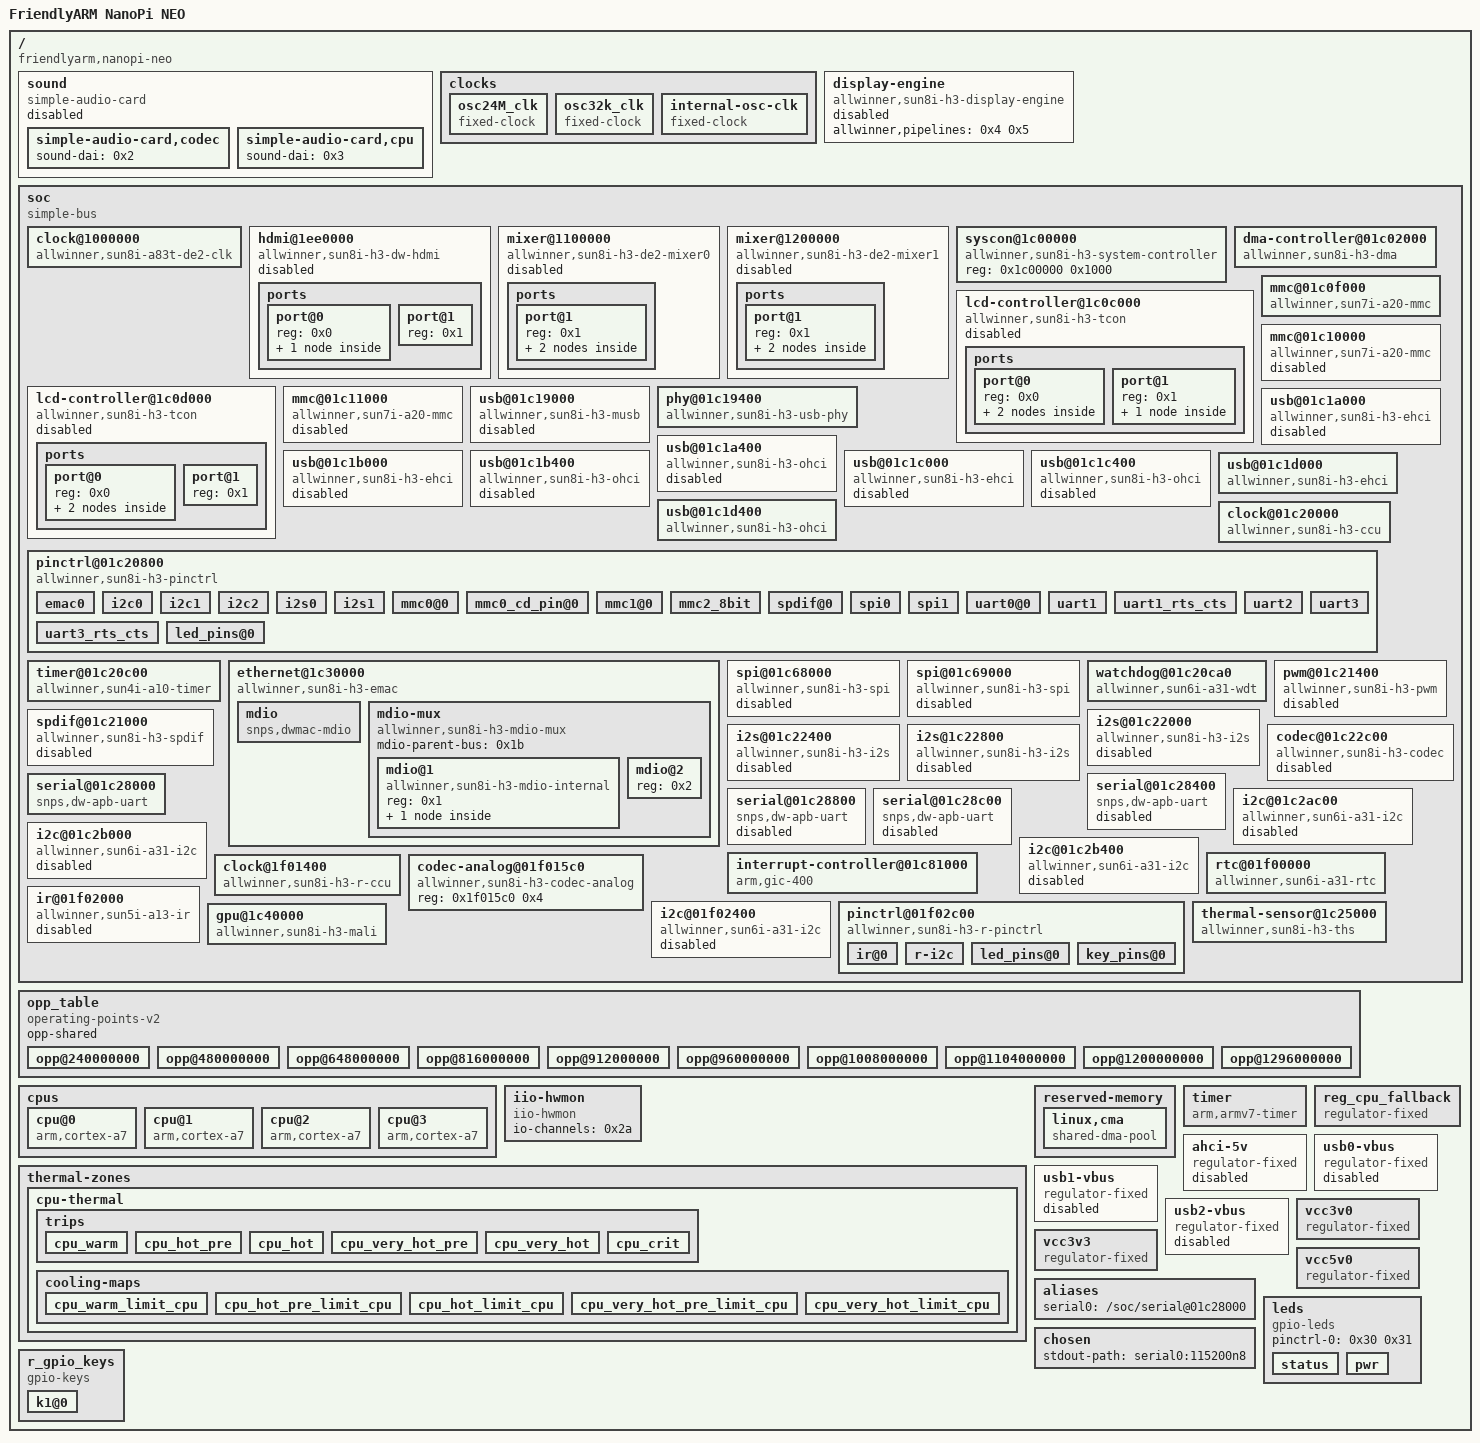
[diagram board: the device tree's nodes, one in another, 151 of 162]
/dts-v1/;

/ {
	interrupt-parent = <0x1>;
	#address-cells = <0x1>;
	#size-cells = <0x1>;
	model = "FriendlyARM NanoPi NEO";
	compatible = "friendlyarm,nanopi-neo", "allwinner,sun8i-h3";

	sound {
		compatible = "simple-audio-card";
		simple-audio-card,format = "i2s";
		simple-audio-card,name = "allwinner,hdmi";
		simple-audio-card,mclk-fs = <0x100>;
		status = "disabled";
		linux,phandle = <0x34>;
		phandle = <0x34>;

		simple-audio-card,codec {
			sound-dai = <0x2>;
		};

		simple-audio-card,cpu {
			sound-dai = <0x3>;
		};
	};

	clocks {
		#address-cells = <0x1>;
		#size-cells = <0x1>;
		ranges;

		osc24M_clk {
			#clock-cells = <0x0>;
			compatible = "fixed-clock";
			clock-frequency = <0x16e3600>;
			clock-output-names = "osc24M";
			linux,phandle = <0x17>;
			phandle = <0x17>;
		};

		osc32k_clk {
			#clock-cells = <0x0>;
			compatible = "fixed-clock";
			clock-frequency = <0x8000>;
			clock-output-names = "osc32k";
			linux,phandle = <0x18>;
			phandle = <0x18>;
		};

		internal-osc-clk {
			#clock-cells = <0x0>;
			compatible = "fixed-clock";
			clock-frequency = <0xf42400>;
			clock-accuracy = <0x11e1a300>;
			clock-output-names = "iosc";
			linux,phandle = <0x24>;
			phandle = <0x24>;
		};
	};

	display-engine {
		compatible = "allwinner,sun8i-h3-display-engine";
		allwinner,pipelines = <0x4 0x5>;
		status = "disabled";
		linux,phandle = <0x35>;
		phandle = <0x35>;
	};

	soc {
		compatible = "simple-bus";
		#address-cells = <0x1>;
		#size-cells = <0x1>;
		ranges;

		clock@1000000 {
			reg = <0x1000000 0x100000>;
			clocks = <0x6 0x30 0x6 0x65>;
			clock-names = "bus", "mod";
			resets = <0x6 0x22>;
			#clock-cells = <0x1>;
			#reset-cells = <0x1>;
			assigned-clocks = <0x6 0x65>;
			assigned-clock-parents = <0x6 0xd>;
			assigned-clock-rates = <0x19bfcc00>;
			compatible = "allwinner,sun8i-a83t-de2-clk";
			linux,phandle = <0x8>;
			phandle = <0x8>;
		};

		hdmi@1ee0000 {
			#sound-dai-cells = <0x0>;
			compatible = "allwinner,sun8i-h3-dw-hdmi";
			reg = <0x1ee0000 0x10000 0x1ef0000 0x10000>;
			reg-io-width = <0x1>;
			interrupts = <0x0 0x58 0x4>;
			clocks = <0x6 0x2f 0x6 0x6f 0x6 0x70>;
			clock-names = "iahb", "isfr", "ddc";
			resets = <0x6 0x20 0x6 0x21>;
			reset-names = "hdmi", "ddc";
			status = "disabled";
			linux,phandle = <0x2>;
			phandle = <0x2>;

			ports {
				#address-cells = <0x1>;
				#size-cells = <0x0>;

				port@0 {
					#address-cells = <0x1>;
					#size-cells = <0x0>;
					reg = <0x0>;
					linux,phandle = <0x36>;
					phandle = <0x36>;

					endpoint@0 {
						reg = <0x0>;
						remote-endpoint = <0x7>;
						linux,phandle = <0xf>;
						phandle = <0xf>;
					};
				};

				port@1 {
					#address-cells = <0x1>;
					#size-cells = <0x0>;
					reg = <0x1>;
					linux,phandle = <0x37>;
					phandle = <0x37>;
				};
			};
		};

		mixer@1100000 {
			compatible = "allwinner,sun8i-h3-de2-mixer0";
			reg = <0x1100000 0x100000>;
			clocks = <0x8 0x0 0x8 0x6>;
			clock-names = "bus", "mod";
			resets = <0x8 0x0>;
			status = "disabled";
			linux,phandle = <0x4>;
			phandle = <0x4>;

			ports {
				#address-cells = <0x1>;
				#size-cells = <0x0>;

				port@1 {
					#address-cells = <0x1>;
					#size-cells = <0x0>;
					reg = <0x1>;
					linux,phandle = <0x38>;
					phandle = <0x38>;

					endpoint@0 {
						reg = <0x0>;
						remote-endpoint = <0x9>;
						linux,phandle = <0xd>;
						phandle = <0xd>;
					};

					endpoint@1 {
						reg = <0x1>;
						remote-endpoint = <0xa>;
						linux,phandle = <0x10>;
						phandle = <0x10>;
					};
				};
			};
		};

		mixer@1200000 {
			compatible = "allwinner,sun8i-h3-de2-mixer1";
			reg = <0x1200000 0x100000>;
			clocks = <0x8 0x1 0x8 0x7>;
			clock-names = "bus", "mod";
			status = "disabled";
			resets = <0x8 0x2>;
			linux,phandle = <0x5>;
			phandle = <0x5>;

			ports {
				#address-cells = <0x1>;
				#size-cells = <0x0>;

				port@1 {
					#address-cells = <0x1>;
					#size-cells = <0x0>;
					reg = <0x1>;
					linux,phandle = <0x39>;
					phandle = <0x39>;

					endpoint@0 {
						reg = <0x0>;
						remote-endpoint = <0xb>;
						linux,phandle = <0xe>;
						phandle = <0xe>;
					};

					endpoint@1 {
						reg = <0x1>;
						remote-endpoint = <0xc>;
						linux,phandle = <0x11>;
						phandle = <0x11>;
					};
				};
			};
		};

		syscon@1c00000 {
			compatible = "allwinner,sun8i-h3-system-controller", "syscon";
			reg = <0x1c00000 0x1000>;
			linux,phandle = <0x19>;
			phandle = <0x19>;
		};

		dma-controller@01c02000 {
			compatible = "allwinner,sun8i-h3-dma";
			reg = <0x1c02000 0x1000>;
			interrupts = <0x0 0x32 0x4>;
			clocks = <0x6 0x15>;
			resets = <0x6 0x6>;
			#dma-cells = <0x1>;
			linux,phandle = <0x1c>;
			phandle = <0x1c>;
		};

		lcd-controller@1c0c000 {
			compatible = "allwinner,sun8i-h3-tcon";
			reg = <0x1c0c000 0x1000>;
			interrupts = <0x0 0x56 0x4>;
			clocks = <0x6 0x2a 0x6 0x66>;
			clock-names = "ahb", "tcon-ch1";
			resets = <0x6 0x1b>;
			reset-names = "lcd";
			status = "disabled";
			linux,phandle = <0x3a>;
			phandle = <0x3a>;

			ports {
				#address-cells = <0x1>;
				#size-cells = <0x0>;

				port@0 {
					#address-cells = <0x1>;
					#size-cells = <0x0>;
					reg = <0x0>;
					linux,phandle = <0x3b>;
					phandle = <0x3b>;

					endpoint@0 {
						reg = <0x0>;
						remote-endpoint = <0xd>;
						linux,phandle = <0x9>;
						phandle = <0x9>;
					};

					endpoint@1 {
						reg = <0x1>;
						remote-endpoint = <0xe>;
						linux,phandle = <0xb>;
						phandle = <0xb>;
					};
				};

				port@1 {
					#address-cells = <0x1>;
					#size-cells = <0x0>;
					reg = <0x1>;
					linux,phandle = <0x3c>;
					phandle = <0x3c>;

					endpoint@1 {
						reg = <0x1>;
						remote-endpoint = <0xf>;
						linux,phandle = <0x7>;
						phandle = <0x7>;
					};
				};
			};
		};

		lcd-controller@1c0d000 {
			compatible = "allwinner,sun8i-h3-tcon";
			reg = <0x1c0d000 0x1000>;
			interrupts = <0x0 0x57 0x4>;
			clocks = <0x6 0x2b 0x6 0x67>;
			clock-names = "ahb", "tcon-ch1";
			resets = <0x6 0x1c>;
			reset-names = "lcd";
			status = "disabled";
			linux,phandle = <0x3d>;
			phandle = <0x3d>;

			ports {
				#address-cells = <0x1>;
				#size-cells = <0x0>;

				port@0 {
					#address-cells = <0x1>;
					#size-cells = <0x0>;
					reg = <0x0>;
					linux,phandle = <0x3e>;
					phandle = <0x3e>;

					endpoint@0 {
						reg = <0x0>;
						remote-endpoint = <0x10>;
						linux,phandle = <0xa>;
						phandle = <0xa>;
					};

					endpoint@1 {
						reg = <0x1>;
						remote-endpoint = <0x11>;
						linux,phandle = <0xc>;
						phandle = <0xc>;
					};
				};

				port@1 {
					#address-cells = <0x1>;
					#size-cells = <0x0>;
					reg = <0x1>;
					linux,phandle = <0x3f>;
					phandle = <0x3f>;
				};
			};
		};

		mmc@01c0f000 {
			reg = <0x1c0f000 0x1000>;
			resets = <0x6 0x7>;
			reset-names = "ahb";
			interrupts = <0x0 0x3c 0x4>;
			status = "okay";
			#address-cells = <0x1>;
			#size-cells = <0x0>;
			compatible = "allwinner,sun7i-a20-mmc";
			clocks = <0x6 0x16 0x6 0x47 0x6 0x49 0x6 0x48>;
			clock-names = "ahb", "mmc", "output", "sample";
			bus-width = <0x4>;
			cd-gpios = <0x12 0x5 0x6 0x0>;
			cd-inverted;
			pinctrl-names = "default";
			pinctrl-0 = <0x13 0x14>;
			vmmc-supply = <0x15>;
			linux,phandle = <0x40>;
			phandle = <0x40>;
		};

		mmc@01c10000 {
			reg = <0x1c10000 0x1000>;
			resets = <0x6 0x8>;
			reset-names = "ahb";
			interrupts = <0x0 0x3d 0x4>;
			status = "disabled";
			#address-cells = <0x1>;
			#size-cells = <0x0>;
			compatible = "allwinner,sun7i-a20-mmc";
			clocks = <0x6 0x17 0x6 0x4a 0x6 0x4c 0x6 0x4b>;
			clock-names = "ahb", "mmc", "output", "sample";
			linux,phandle = <0x41>;
			phandle = <0x41>;
		};

		mmc@01c11000 {
			reg = <0x1c11000 0x1000>;
			resets = <0x6 0x9>;
			reset-names = "ahb";
			interrupts = <0x0 0x3e 0x4>;
			status = "disabled";
			#address-cells = <0x1>;
			#size-cells = <0x0>;
			compatible = "allwinner,sun7i-a20-mmc";
			clocks = <0x6 0x18 0x6 0x4d 0x6 0x4f 0x6 0x4e>;
			clock-names = "ahb", "mmc", "output", "sample";
			linux,phandle = <0x42>;
			phandle = <0x42>;
		};

		usb@01c19000 {
			compatible = "allwinner,sun8i-h3-musb";
			reg = <0x1c19000 0x400>;
			clocks = <0x6 0x20>;
			resets = <0x6 0x11>;
			interrupts = <0x0 0x47 0x4>;
			interrupt-names = "mc";
			phys = <0x16 0x0>;
			phy-names = "usb";
			extcon = <0x16 0x0>;
			status = "disabled";
			linux,phandle = <0x43>;
			phandle = <0x43>;
		};

		phy@01c19400 {
			compatible = "allwinner,sun8i-h3-usb-phy";
			reg = <0x1c19400 0x2c 0x1c1a800 0x4 0x1c1b800 0x4 0x1c1c800 0x4 0x1c1d800 0x4>;
			reg-names = "phy_ctrl", "pmu0", "pmu1", "pmu2", "pmu3";
			clocks = <0x6 0x58 0x6 0x59 0x6 0x5a 0x6 0x5b>;
			clock-names = "usb0_phy", "usb1_phy", "usb2_phy", "usb3_phy";
			resets = <0x6 0x0 0x6 0x1 0x6 0x2 0x6 0x3>;
			reset-names = "usb0_reset", "usb1_reset", "usb2_reset", "usb3_reset";
			status = "okay";
			#phy-cells = <0x1>;
			linux,phandle = <0x16>;
			phandle = <0x16>;
		};

		usb@01c1a000 {
			compatible = "allwinner,sun8i-h3-ehci", "generic-ehci";
			reg = <0x1c1a000 0x100>;
			interrupts = <0x0 0x48 0x4>;
			clocks = <0x6 0x21 0x6 0x25>;
			resets = <0x6 0x12 0x6 0x16>;
			status = "disabled";
			linux,phandle = <0x44>;
			phandle = <0x44>;
		};

		usb@01c1a400 {
			compatible = "allwinner,sun8i-h3-ohci", "generic-ohci";
			reg = <0x1c1a400 0x100>;
			interrupts = <0x0 0x49 0x4>;
			clocks = <0x6 0x21 0x6 0x25 0x6 0x5c>;
			resets = <0x6 0x12 0x6 0x16>;
			status = "disabled";
			linux,phandle = <0x45>;
			phandle = <0x45>;
		};

		usb@01c1b000 {
			compatible = "allwinner,sun8i-h3-ehci", "generic-ehci";
			reg = <0x1c1b000 0x100>;
			interrupts = <0x0 0x4a 0x4>;
			clocks = <0x6 0x22 0x6 0x26>;
			resets = <0x6 0x13 0x6 0x17>;
			phys = <0x16 0x1>;
			phy-names = "usb";
			status = "disabled";
			linux,phandle = <0x46>;
			phandle = <0x46>;
		};

		usb@01c1b400 {
			compatible = "allwinner,sun8i-h3-ohci", "generic-ohci";
			reg = <0x1c1b400 0x100>;
			interrupts = <0x0 0x4b 0x4>;
			clocks = <0x6 0x22 0x6 0x26 0x6 0x5d>;
			resets = <0x6 0x13 0x6 0x17>;
			phys = <0x16 0x1>;
			phy-names = "usb";
			status = "disabled";
			linux,phandle = <0x47>;
			phandle = <0x47>;
		};

		usb@01c1c000 {
			compatible = "allwinner,sun8i-h3-ehci", "generic-ehci";
			reg = <0x1c1c000 0x100>;
			interrupts = <0x0 0x4c 0x4>;
			clocks = <0x6 0x23 0x6 0x27>;
			resets = <0x6 0x14 0x6 0x18>;
			phys = <0x16 0x2>;
			phy-names = "usb";
			status = "disabled";
			linux,phandle = <0x48>;
			phandle = <0x48>;
		};

		usb@01c1c400 {
			compatible = "allwinner,sun8i-h3-ohci", "generic-ohci";
			reg = <0x1c1c400 0x100>;
			interrupts = <0x0 0x4d 0x4>;
			clocks = <0x6 0x23 0x6 0x27 0x6 0x5e>;
			resets = <0x6 0x14 0x6 0x18>;
			phys = <0x16 0x2>;
			phy-names = "usb";
			status = "disabled";
			linux,phandle = <0x49>;
			phandle = <0x49>;
		};

		usb@01c1d000 {
			compatible = "allwinner,sun8i-h3-ehci", "generic-ehci";
			reg = <0x1c1d000 0x100>;
			interrupts = <0x0 0x4e 0x4>;
			clocks = <0x6 0x24 0x6 0x28>;
			resets = <0x6 0x15 0x6 0x19>;
			phys = <0x16 0x3>;
			phy-names = "usb";
			status = "okay";
			linux,phandle = <0x4a>;
			phandle = <0x4a>;
		};

		usb@01c1d400 {
			compatible = "allwinner,sun8i-h3-ohci", "generic-ohci";
			reg = <0x1c1d400 0x100>;
			interrupts = <0x0 0x4f 0x4>;
			clocks = <0x6 0x24 0x6 0x28 0x6 0x5f>;
			resets = <0x6 0x15 0x6 0x19>;
			phys = <0x16 0x3>;
			phy-names = "usb";
			status = "okay";
			linux,phandle = <0x4b>;
			phandle = <0x4b>;
		};

		clock@01c20000 {
			reg = <0x1c20000 0x400>;
			clocks = <0x17 0x18>;
			clock-names = "hosc", "losc";
			#clock-cells = <0x1>;
			#reset-cells = <0x1>;
			compatible = "allwinner,sun8i-h3-ccu";
			linux,phandle = <0x6>;
			phandle = <0x6>;
		};

		pinctrl@01c20800 {
			reg = <0x1c20800 0x400>;
			interrupts = <0x0 0xb 0x4 0x0 0x11 0x4>;
			clocks = <0x6 0x36 0x17 0x18>;
			clock-names = "apb", "hosc", "losc";
			gpio-controller;
			#gpio-cells = <0x3>;
			interrupt-controller;
			#interrupt-cells = <0x3>;
			compatible = "allwinner,sun8i-h3-pinctrl";
			linux,phandle = <0x12>;
			phandle = <0x12>;

			emac0 {
				pins = "PD0", "PD1", "PD2", "PD3", "PD4", "PD5", "PD7", "PD8", "PD9", "PD10", "PD12", "PD13", "PD15", "PD16", "PD17";
				function = "emac";
				drive-strength = <0x28>;
				linux,phandle = <0x4c>;
				phandle = <0x4c>;
			};

			i2c0 {
				pins = "PA11", "PA12";
				function = "i2c0";
				linux,phandle = <0x21>;
				phandle = <0x21>;
			};

			i2c1 {
				pins = "PA18", "PA19";
				function = "i2c1";
				linux,phandle = <0x22>;
				phandle = <0x22>;
			};

			i2c2 {
				pins = "PE12", "PE13";
				function = "i2c2";
				linux,phandle = <0x23>;
				phandle = <0x23>;
			};

			i2s0 {
				pins = "PA18", "PA19", "PA20", "PA21";
				function = "i2s0";
				linux,phandle = <0x4d>;
				phandle = <0x4d>;
			};

			i2s1 {
				pins = "PG10", "PG11", "PG12", "PG13";
				function = "i2s1";
				linux,phandle = <0x4e>;
				phandle = <0x4e>;
			};

			mmc0@0 {
				pins = "PF0", "PF1", "PF2", "PF3", "PF4", "PF5";
				function = "mmc0";
				drive-strength = <0x1e>;
				bias-pull-up;
				linux,phandle = <0x13>;
				phandle = <0x13>;
			};

			mmc0_cd_pin@0 {
				pins = "PF6";
				function = "gpio_in";
				bias-pull-up;
				linux,phandle = <0x14>;
				phandle = <0x14>;
			};

			mmc1@0 {
				pins = "PG0", "PG1", "PG2", "PG3", "PG4", "PG5";
				function = "mmc1";
				drive-strength = <0x1e>;
				bias-pull-up;
				linux,phandle = <0x4f>;
				phandle = <0x4f>;
			};

			mmc2_8bit {
				pins = "PC5", "PC6", "PC8", "PC9", "PC10", "PC11", "PC12", "PC13", "PC14", "PC15", "PC16";
				function = "mmc2";
				drive-strength = <0x1e>;
				bias-pull-up;
				linux,phandle = <0x50>;
				phandle = <0x50>;
			};

			spdif@0 {
				pins = "PA17";
				function = "spdif";
				linux,phandle = <0x51>;
				phandle = <0x51>;
			};

			spi0 {
				pins = "PC0", "PC1", "PC2", "PC3";
				function = "spi0";
				linux,phandle = <0x1d>;
				phandle = <0x1d>;
			};

			spi1 {
				pins = "PA15", "PA16", "PA14", "PA13";
				function = "spi1";
				linux,phandle = <0x1e>;
				phandle = <0x1e>;
			};

			uart0@0 {
				pins = "PA4", "PA5";
				function = "uart0";
				linux,phandle = <0x20>;
				phandle = <0x20>;
			};

			uart1 {
				pins = "PG6", "PG7";
				function = "uart1";
				linux,phandle = <0x52>;
				phandle = <0x52>;
			};

			uart1_rts_cts {
				pins = "PG8", "PG9";
				function = "uart1";
				linux,phandle = <0x53>;
				phandle = <0x53>;
			};

			uart2 {
				pins = "PA0", "PA1";
				function = "uart2";
				linux,phandle = <0x54>;
				phandle = <0x54>;
			};

			uart3 {
				pins = "PA13", "PA14";
				function = "uart3";
				linux,phandle = <0x55>;
				phandle = <0x55>;
			};

			uart3_rts_cts {
				pins = "PA15", "PA16";
				function = "uart3";
				linux,phandle = <0x56>;
				phandle = <0x56>;
			};

			led_pins@0 {
				pins = "PA10";
				function = "gpio_out";
				linux,phandle = <0x30>;
				phandle = <0x30>;
			};
		};

		timer@01c20c00 {
			compatible = "allwinner,sun4i-a10-timer";
			reg = <0x1c20c00 0xa0>;
			interrupts = <0x0 0x12 0x4 0x0 0x13 0x4>;
			clocks = <0x17>;
		};

		ethernet@1c30000 {
			compatible = "allwinner,sun8i-h3-emac";
			syscon = <0x19>;
			reg = <0x1c30000 0x10000>;
			interrupts = <0x0 0x52 0x4>;
			interrupt-names = "macirq";
			resets = <0x6 0xc>;
			reset-names = "stmmaceth";
			clocks = <0x6 0x1b>;
			clock-names = "stmmaceth";
			#address-cells = <0x1>;
			#size-cells = <0x0>;
			status = "okay";
			phy-handle = <0x1a>;
			phy-mode = "mii";
			allwinner,leds-active-low;
			linux,phandle = <0x57>;
			phandle = <0x57>;

			mdio {
				#address-cells = <0x1>;
				#size-cells = <0x0>;
				compatible = "snps,dwmac-mdio";
				linux,phandle = <0x1b>;
				phandle = <0x1b>;
			};

			mdio-mux {
				compatible = "allwinner,sun8i-h3-mdio-mux";
				#address-cells = <0x1>;
				#size-cells = <0x0>;
				mdio-parent-bus = <0x1b>;

				mdio@1 {
					compatible = "allwinner,sun8i-h3-mdio-internal";
					reg = <0x1>;
					#address-cells = <0x1>;
					#size-cells = <0x0>;
					linux,phandle = <0x58>;
					phandle = <0x58>;

					ethernet-phy@1 {
						compatible = "ethernet-phy-ieee802.3-c22";
						reg = <0x1>;
						clocks = <0x6 0x43>;
						resets = <0x6 0x27>;
						linux,phandle = <0x1a>;
						phandle = <0x1a>;
					};
				};

				mdio@2 {
					reg = <0x2>;
					#address-cells = <0x1>;
					#size-cells = <0x0>;
					linux,phandle = <0x59>;
					phandle = <0x59>;
				};
			};
		};

		spi@01c68000 {
			compatible = "allwinner,sun8i-h3-spi";
			reg = <0x1c68000 0x1000>;
			interrupts = <0x0 0x41 0x4>;
			clocks = <0x6 0x1e 0x6 0x52>;
			clock-names = "ahb", "mod";
			dmas = <0x1c 0x17 0x1c 0x17>;
			dma-names = "rx", "tx";
			pinctrl-names = "default";
			pinctrl-0 = <0x1d>;
			resets = <0x6 0xf>;
			status = "disabled";
			#address-cells = <0x1>;
			#size-cells = <0x0>;
			linux,phandle = <0x5a>;
			phandle = <0x5a>;
		};

		spi@01c69000 {
			compatible = "allwinner,sun8i-h3-spi";
			reg = <0x1c69000 0x1000>;
			interrupts = <0x0 0x42 0x4>;
			clocks = <0x6 0x1f 0x6 0x53>;
			clock-names = "ahb", "mod";
			dmas = <0x1c 0x18 0x1c 0x18>;
			dma-names = "rx", "tx";
			pinctrl-names = "default";
			pinctrl-0 = <0x1e>;
			resets = <0x6 0x10>;
			status = "disabled";
			#address-cells = <0x1>;
			#size-cells = <0x0>;
			linux,phandle = <0x5b>;
			phandle = <0x5b>;
		};

		watchdog@01c20ca0 {
			compatible = "allwinner,sun6i-a31-wdt";
			reg = <0x1c20ca0 0x20>;
			interrupts = <0x0 0x19 0x4>;
			linux,phandle = <0x5c>;
			phandle = <0x5c>;
		};

		spdif@01c21000 {
			#sound-dai-cells = <0x0>;
			compatible = "allwinner,sun8i-h3-spdif";
			reg = <0x1c21000 0x400>;
			interrupts = <0x0 0xc 0x4>;
			clocks = <0x6 0x35 0x6 0x57>;
			resets = <0x6 0x29>;
			clock-names = "apb", "spdif";
			dmas = <0x1c 0x2>;
			dma-names = "tx";
			status = "disabled";
			linux,phandle = <0x5d>;
			phandle = <0x5d>;
		};

		pwm@01c21400 {
			compatible = "allwinner,sun8i-h3-pwm";
			reg = <0x1c21400 0x8>;
			clocks = <0x17>;
			#pwm-cells = <0x3>;
			status = "disabled";
			linux,phandle = <0x5e>;
			phandle = <0x5e>;
		};

		i2s@01c22000 {
			#sound-dai-cells = <0x0>;
			compatible = "allwinner,sun8i-h3-i2s";
			reg = <0x1c22000 0x400>;
			interrupts = <0x0 0xd 0x4>;
			clocks = <0x6 0x38 0x6 0x54>;
			clock-names = "apb", "mod";
			dmas = <0x1c 0x3 0x1c 0x3>;
			resets = <0x6 0x2b>;
			dma-names = "rx", "tx";
			status = "disabled";
			linux,phandle = <0x5f>;
			phandle = <0x5f>;
		};

		i2s@01c22400 {
			#sound-dai-cells = <0x0>;
			compatible = "allwinner,sun8i-h3-i2s";
			reg = <0x1c22400 0x400>;
			interrupts = <0x0 0xe 0x4>;
			clocks = <0x6 0x39 0x6 0x55>;
			clock-names = "apb", "mod";
			dmas = <0x1c 0x4 0x1c 0x4>;
			resets = <0x6 0x2c>;
			dma-names = "rx", "tx";
			status = "disabled";
			linux,phandle = <0x60>;
			phandle = <0x60>;
		};

		i2s@1c22800 {
			#sound-dai-cells = <0x0>;
			compatible = "allwinner,sun8i-h3-i2s";
			reg = <0x1c22800 0x400>;
			interrupts = <0x0 0xf 0x4>;
			clocks = <0x6 0x3a 0x6 0x56>;
			clock-names = "apb", "mod";
			dmas = <0x1c 0x1b>;
			resets = <0x6 0x2d>;
			dma-names = "tx";
			status = "disabled";
			linux,phandle = <0x3>;
			phandle = <0x3>;
		};

		codec@01c22c00 {
			#sound-dai-cells = <0x0>;
			compatible = "allwinner,sun8i-h3-codec";
			reg = <0x1c22c00 0x400>;
			interrupts = <0x0 0x1d 0x4>;
			clocks = <0x6 0x34 0x6 0x6d>;
			clock-names = "apb", "codec";
			resets = <0x6 0x28>;
			dmas = <0x1c 0xf 0x1c 0xf>;
			dma-names = "rx", "tx";
			allwinner,codec-analog-controls = <0x1f>;
			status = "disabled";
			linux,phandle = <0x61>;
			phandle = <0x61>;
		};

		serial@01c28000 {
			compatible = "snps,dw-apb-uart";
			reg = <0x1c28000 0x400>;
			interrupts = <0x0 0x0 0x4>;
			reg-shift = <0x2>;
			reg-io-width = <0x4>;
			clocks = <0x6 0x3e>;
			resets = <0x6 0x31>;
			dmas = <0x1c 0x6 0x1c 0x6>;
			dma-names = "rx", "tx";
			status = "okay";
			pinctrl-names = "default";
			pinctrl-0 = <0x20>;
			linux,phandle = <0x62>;
			phandle = <0x62>;
		};

		serial@01c28400 {
			compatible = "snps,dw-apb-uart";
			reg = <0x1c28400 0x400>;
			interrupts = <0x0 0x1 0x4>;
			reg-shift = <0x2>;
			reg-io-width = <0x4>;
			clocks = <0x6 0x3f>;
			resets = <0x6 0x32>;
			dmas = <0x1c 0x7 0x1c 0x7>;
			dma-names = "rx", "tx";
			status = "disabled";
			linux,phandle = <0x63>;
			phandle = <0x63>;
		};

		serial@01c28800 {
			compatible = "snps,dw-apb-uart";
			reg = <0x1c28800 0x400>;
			interrupts = <0x0 0x2 0x4>;
			reg-shift = <0x2>;
			reg-io-width = <0x4>;
			clocks = <0x6 0x40>;
			resets = <0x6 0x33>;
			dmas = <0x1c 0x8 0x1c 0x8>;
			dma-names = "rx", "tx";
			status = "disabled";
			linux,phandle = <0x64>;
			phandle = <0x64>;
		};

		serial@01c28c00 {
			compatible = "snps,dw-apb-uart";
			reg = <0x1c28c00 0x400>;
			interrupts = <0x0 0x3 0x4>;
			reg-shift = <0x2>;
			reg-io-width = <0x4>;
			clocks = <0x6 0x41>;
			resets = <0x6 0x34>;
			dmas = <0x1c 0x9 0x1c 0x9>;
			dma-names = "rx", "tx";
			status = "disabled";
			linux,phandle = <0x65>;
			phandle = <0x65>;
		};

		i2c@01c2ac00 {
			compatible = "allwinner,sun6i-a31-i2c";
			reg = <0x1c2ac00 0x400>;
			interrupts = <0x0 0x6 0x4>;
			clocks = <0x6 0x3b>;
			resets = <0x6 0x2e>;
			pinctrl-names = "default";
			pinctrl-0 = <0x21>;
			status = "disabled";
			#address-cells = <0x1>;
			#size-cells = <0x0>;
			linux,phandle = <0x66>;
			phandle = <0x66>;
		};

		i2c@01c2b000 {
			compatible = "allwinner,sun6i-a31-i2c";
			reg = <0x1c2b000 0x400>;
			interrupts = <0x0 0x7 0x4>;
			clocks = <0x6 0x3c>;
			resets = <0x6 0x2f>;
			pinctrl-names = "default";
			pinctrl-0 = <0x22>;
			status = "disabled";
			#address-cells = <0x1>;
			#size-cells = <0x0>;
			linux,phandle = <0x67>;
			phandle = <0x67>;
		};

		i2c@01c2b400 {
			compatible = "allwinner,sun6i-a31-i2c";
			reg = <0x1c2b400 0x400>;
			interrupts = <0x0 0x8 0x4>;
			clocks = <0x6 0x3d>;
			resets = <0x6 0x30>;
			pinctrl-names = "default";
			pinctrl-0 = <0x23>;
			status = "disabled";
			#address-cells = <0x1>;
			#size-cells = <0x0>;
			linux,phandle = <0x68>;
			phandle = <0x68>;
		};

		interrupt-controller@01c81000 {
			compatible = "arm,gic-400";
			reg = <0x1c81000 0x1000 0x1c82000 0x2000 0x1c84000 0x2000 0x1c86000 0x2000>;
			interrupt-controller;
			#interrupt-cells = <0x3>;
			interrupts = <0x1 0x9 0xf04>;
			linux,phandle = <0x1>;
			phandle = <0x1>;
		};

		rtc@01f00000 {
			compatible = "allwinner,sun6i-a31-rtc";
			reg = <0x1f00000 0x54>;
			interrupts = <0x0 0x28 0x4 0x0 0x29 0x4>;
			linux,phandle = <0x69>;
			phandle = <0x69>;
		};

		clock@1f01400 {
			compatible = "allwinner,sun8i-h3-r-ccu";
			reg = <0x1f01400 0x100>;
			clocks = <0x17 0x18 0x24 0x6 0x9>;
			clock-names = "hosc", "losc", "iosc", "pll-periph";
			#clock-cells = <0x1>;
			#reset-cells = <0x1>;
			linux,phandle = <0x25>;
			phandle = <0x25>;
		};

		codec-analog@01f015c0 {
			compatible = "allwinner,sun8i-h3-codec-analog";
			reg = <0x1f015c0 0x4>;
			linux,phandle = <0x1f>;
			phandle = <0x1f>;
		};

		ir@01f02000 {
			compatible = "allwinner,sun5i-a13-ir";
			clocks = <0x25 0x4 0x25 0xb>;
			clock-names = "apb", "ir";
			resets = <0x25 0x0>;
			interrupts = <0x0 0x25 0x4>;
			reg = <0x1f02000 0x40>;
			status = "disabled";
			linux,phandle = <0x6a>;
			phandle = <0x6a>;
		};

		i2c@01f02400 {
			compatible = "allwinner,sun6i-a31-i2c";
			reg = <0x1f02400 0x400>;
			interrupts = <0x0 0x2c 0x4>;
			pinctrl-names = "default";
			pinctrl-0 = <0x26>;
			clocks = <0x25 0x9>;
			clock-frequency = <0x186a0>;
			resets = <0x25 0x5>;
			status = "disabled";
			#address-cells = <0x1>;
			#size-cells = <0x0>;
			linux,phandle = <0x6b>;
			phandle = <0x6b>;
		};

		pinctrl@01f02c00 {
			compatible = "allwinner,sun8i-h3-r-pinctrl";
			reg = <0x1f02c00 0x400>;
			interrupts = <0x0 0x2d 0x4>;
			clocks = <0x25 0x3 0x17 0x18>;
			clock-names = "apb", "hosc", "losc";
			gpio-controller;
			#gpio-cells = <0x3>;
			interrupt-controller;
			#interrupt-cells = <0x3>;
			linux,phandle = <0x32>;
			phandle = <0x32>;

			ir@0 {
				pins = "PL11";
				function = "s_cir_rx";
				linux,phandle = <0x6c>;
				phandle = <0x6c>;
			};

			r-i2c {
				pins = "PL0", "PL1";
				function = "s_i2c";
				linux,phandle = <0x26>;
				phandle = <0x26>;
			};

			led_pins@0 {
				pins = "PL10";
				function = "gpio_out";
				linux,phandle = <0x31>;
				phandle = <0x31>;
			};

			key_pins@0 {
				pins = "PL3";
				function = "gpio_in";
				linux,phandle = <0x33>;
				phandle = <0x33>;
			};
		};

		thermal-sensor@1c25000 {
			compatible = "allwinner,sun8i-h3-ths";
			reg = <0x1c25000 0x100>;
			clocks = <0x6 0x37 0x6 0x45>;
			clock-names = "bus", "mod";
			resets = <0x6 0x2a>;
			#thermal-sensor-cells = <0x0>;
			#io-channel-cells = <0x0>;
			linux,phandle = <0x2a>;
			phandle = <0x2a>;
		};

		gpu@1c40000 {
			compatible = "allwinner,sun8i-h3-mali", "allwinner,sun7i-a20-mali", "arm,mali-400";
			reg = <0x1c40000 0x10000>;
			interrupts = <0x0 0x61 0x4 0x0 0x62 0x4 0x0 0x63 0x4 0x0 0x64 0x4 0x0 0x66 0x4 0x0 0x67 0x4 0x0 0x65 0x4>;
			interrupt-names = "gp", "gpmmu", "pp0", "ppmmu0", "pp1", "ppmmu1", "pmu";
			clocks = <0x6 0x31 0x6 0x72>;
			clock-names = "bus", "core";
			resets = <0x6 0x23>;
			memory-region = <0x27>;
			assigned-clocks = <0x6 0x72>;
			assigned-clock-rates = <0x16e36000>;
			linux,phandle = <0x6d>;
			phandle = <0x6d>;
		};
	};

	opp_table {
		compatible = "operating-points-v2";
		opp-shared;
		linux,phandle = <0x28>;
		phandle = <0x28>;

		opp@240000000 {
			opp-hz = <0x0 0xe4e1c00>;
			opp-microvolt = <0xef420 0xef420 0x142440>;
			clock-latency-ns = <0x3b9b0>;
		};

		opp@480000000 {
			opp-hz = <0x0 0x1c9c3800>;
			opp-microvolt = <0xef420 0xef420 0x142440>;
			clock-latency-ns = <0x3b9b0>;
		};

		opp@648000000 {
			opp-hz = <0x0 0x269fb200>;
			opp-microvolt = <0xf4240 0xf4240 0x142440>;
			clock-latency-ns = <0x3b9b0>;
		};

		opp@816000000 {
			opp-hz = <0x0 0x30a32c00>;
			opp-microvolt = <0xf9060 0xf9060 0x142440>;
			clock-latency-ns = <0x3b9b0>;
		};

		opp@912000000 {
			opp-hz = <0x0 0x365c0400>;
			opp-microvolt = <0xfde80 0xfde80 0x142440>;
			clock-latency-ns = <0x3b9b0>;
		};

		opp@960000000 {
			opp-hz = <0x0 0x39387000>;
			opp-microvolt = <0x107ac0 0x107ac0 0x142440>;
			clock-latency-ns = <0x3b9b0>;
		};

		opp@1008000000 {
			opp-hz = <0x0 0x3c14dc00>;
			opp-microvolt = <0x116520 0x116520 0x142440>;
			clock-latency-ns = <0x3b9b0>;
		};

		opp@1104000000 {
			opp-hz = <0x0 0x41cdb400>;
			opp-microvolt = <0x120160 0x120160 0x142440>;
			clock-latency-ns = <0x3b9b0>;
		};

		opp@1200000000 {
			opp-hz = <0x0 0x47868c00>;
			opp-microvolt = <0x12ebc0 0x12ebc0 0x142440>;
			clock-latency-ns = <0x3b9b0>;
		};

		opp@1296000000 {
			opp-hz = <0x0 0x4d3f6400>;
			opp-microvolt = <0x142440 0x142440 0x142440>;
			clock-latency-ns = <0x3b9b0>;
		};
	};

	cpus {
		#address-cells = <0x1>;
		#size-cells = <0x0>;

		cpu@0 {
			compatible = "arm,cortex-a7";
			device_type = "cpu";
			reg = <0x0>;
			clocks = <0x6 0xe>;
			clock-names = "cpu";
			operating-points-v2 = <0x28>;
			cpu-supply = <0x29>;
			#cooling-cells = <0x2>;
			linux,phandle = <0x2c>;
			phandle = <0x2c>;
		};

		cpu@1 {
			compatible = "arm,cortex-a7";
			device_type = "cpu";
			reg = <0x1>;
			operating-points-v2 = <0x28>;
		};

		cpu@2 {
			compatible = "arm,cortex-a7";
			device_type = "cpu";
			reg = <0x2>;
			operating-points-v2 = <0x28>;
		};

		cpu@3 {
			compatible = "arm,cortex-a7";
			device_type = "cpu";
			reg = <0x3>;
			operating-points-v2 = <0x28>;
		};
	};

	iio-hwmon {
		compatible = "iio-hwmon";
		io-channels = <0x2a>;
	};

	thermal-zones {

		cpu-thermal {
			polling-delay-passive = <0xfa>;
			polling-delay = <0x3e8>;
			thermal-sensors = <0x2a>;

			trips {

				cpu_warm {
					temperature = <0xfde8>;
					hysteresis = <0x7d0>;
					type = "passive";
					linux,phandle = <0x2b>;
					phandle = <0x2b>;
				};

				cpu_hot_pre {
					temperature = <0x11170>;
					hysteresis = <0x7d0>;
					type = "passive";
					linux,phandle = <0x2d>;
					phandle = <0x2d>;
				};

				cpu_hot {
					temperature = <0x124f8>;
					hysteresis = <0x7d0>;
					type = "passive";
					linux,phandle = <0x2e>;
					phandle = <0x2e>;
				};

				cpu_very_hot_pre {
					temperature = <0x14c08>;
					hysteresis = <0x7d0>;
					type = "passive";
					linux,phandle = <0x6e>;
					phandle = <0x6e>;
				};

				cpu_very_hot {
					temperature = <0x15f90>;
					hysteresis = <0x7d0>;
					type = "passive";
					linux,phandle = <0x2f>;
					phandle = <0x2f>;
				};

				cpu_crit {
					temperature = <0x19a28>;
					hysteresis = <0x7d0>;
					type = "critical";
					linux,phandle = <0x6f>;
					phandle = <0x6f>;
				};
			};

			cooling-maps {

				cpu_warm_limit_cpu {
					trip = <0x2b>;
					cooling-device = <0x2c 0xffffffff 0x2>;
				};

				cpu_hot_pre_limit_cpu {
					trip = <0x2d>;
					cooling-device = <0x2c 0x2 0x3>;
				};

				cpu_hot_limit_cpu {
					trip = <0x2e>;
					cooling-device = <0x2c 0x3 0x4>;
				};

				cpu_very_hot_pre_limit_cpu {
					trip = <0x2f>;
					cooling-device = <0x2c 0x5 0x6>;
				};

				cpu_very_hot_limit_cpu {
					trip = <0x2f>;
					cooling-device = <0x2c 0x7 0xffffffff>;
				};
			};
		};
	};

	reserved-memory {
		#address-cells = <0x1>;
		#size-cells = <0x1>;
		ranges;

		linux,cma {
			compatible = "shared-dma-pool";
			reusable;
			size = <0x4000000>;
			alignment = <0x2000>;
			linux,cma-default;
			linux,phandle = <0x27>;
			phandle = <0x27>;
		};
	};

	timer {
		compatible = "arm,armv7-timer";
		interrupts = <0x1 0xd 0xf08 0x1 0xe 0xf08 0x1 0xb 0xf08 0x1 0xa 0xf08>;
	};

	reg_cpu_fallback {
		compatible = "regulator-fixed";
		regulator-name = "vdd-cpux-dummy";
		regulator-min-microvolt = <0x124f80>;
		regulator-max-microvolt = <0x124f80>;
		linux,phandle = <0x29>;
		phandle = <0x29>;
	};

	ahci-5v {
		compatible = "regulator-fixed";
		regulator-name = "ahci-5v";
		regulator-min-microvolt = <0x4c4b40>;
		regulator-max-microvolt = <0x4c4b40>;
		regulator-boot-on;
		enable-active-high;
		gpio = <0x12 0x1 0x8 0x0>;
		status = "disabled";
		linux,phandle = <0x70>;
		phandle = <0x70>;
	};

	usb0-vbus {
		compatible = "regulator-fixed";
		regulator-name = "usb0-vbus";
		regulator-min-microvolt = <0x4c4b40>;
		regulator-max-microvolt = <0x4c4b40>;
		enable-active-high;
		gpio = <0x12 0x1 0x9 0x0>;
		status = "disabled";
		linux,phandle = <0x71>;
		phandle = <0x71>;
	};

	usb1-vbus {
		compatible = "regulator-fixed";
		regulator-name = "usb1-vbus";
		regulator-min-microvolt = <0x4c4b40>;
		regulator-max-microvolt = <0x4c4b40>;
		regulator-boot-on;
		enable-active-high;
		gpio = <0x12 0x7 0x6 0x0>;
		status = "disabled";
		linux,phandle = <0x72>;
		phandle = <0x72>;
	};

	usb2-vbus {
		compatible = "regulator-fixed";
		regulator-name = "usb2-vbus";
		regulator-min-microvolt = <0x4c4b40>;
		regulator-max-microvolt = <0x4c4b40>;
		regulator-boot-on;
		enable-active-high;
		gpio = <0x12 0x7 0x3 0x0>;
		status = "disabled";
		linux,phandle = <0x73>;
		phandle = <0x73>;
	};

	vcc3v0 {
		compatible = "regulator-fixed";
		regulator-name = "vcc3v0";
		regulator-min-microvolt = <0x2dc6c0>;
		regulator-max-microvolt = <0x2dc6c0>;
		linux,phandle = <0x74>;
		phandle = <0x74>;
	};

	vcc3v3 {
		compatible = "regulator-fixed";
		regulator-name = "vcc3v3";
		regulator-min-microvolt = <0x325aa0>;
		regulator-max-microvolt = <0x325aa0>;
		linux,phandle = <0x15>;
		phandle = <0x15>;
	};

	vcc5v0 {
		compatible = "regulator-fixed";
		regulator-name = "vcc5v0";
		regulator-min-microvolt = <0x4c4b40>;
		regulator-max-microvolt = <0x4c4b40>;
		linux,phandle = <0x75>;
		phandle = <0x75>;
	};

	aliases {
		serial0 = "/soc/serial@01c28000";
	};

	chosen {
		stdout-path = "serial0:115200n8";
	};

	leds {
		compatible = "gpio-leds";
		pinctrl-names = "default";
		pinctrl-0 = <0x30 0x31>;

		status {
			label = "nanopi:blue:status";
			gpios = <0x12 0x0 0xa 0x0>;
			linux,default-trigger = "heartbeat";
		};

		pwr {
			label = "nanopi:green:pwr";
			gpios = <0x32 0x0 0xa 0x0>;
			default-state = "on";
		};
	};

	r_gpio_keys {
		compatible = "gpio-keys";
		input-name = "k1";
		pinctrl-names = "default";
		pinctrl-0 = <0x33>;

		k1@0 {
			label = "k1";
			linux,code = <0x74>;
			gpios = <0x32 0x0 0x3 0x1>;
		};
	};

	__symbols__ {
		sound_hdmi = "/sound";
		osc24M = "/clocks/osc24M_clk";
		osc32k = "/clocks/osc32k_clk";
		iosc = "/clocks/internal-osc-clk";
		de = "/display-engine";
		display_clocks = "/soc/clock@1000000";
		hdmi = "/soc/hdmi@1ee0000";
		hdmi_in = "/soc/hdmi@1ee0000/ports/port@0";
		hdmi_in_tcon0 = "/soc/hdmi@1ee0000/ports/port@0/endpoint@0";
		hdmi_out = "/soc/hdmi@1ee0000/ports/port@1";
		mixer0 = "/soc/mixer@1100000";
		mixer0_out = "/soc/mixer@1100000/ports/port@1";
		mixer0_out_tcon0 = "/soc/mixer@1100000/ports/port@1/endpoint@0";
		mixer0_out_tcon1 = "/soc/mixer@1100000/ports/port@1/endpoint@1";
		mixer1 = "/soc/mixer@1200000";
		mixer1_out = "/soc/mixer@1200000/ports/port@1";
		mixer1_out_tcon0 = "/soc/mixer@1200000/ports/port@1/endpoint@0";
		mixer1_out_tcon1 = "/soc/mixer@1200000/ports/port@1/endpoint@1";
		syscon = "/soc/syscon@1c00000";
		dma = "/soc/dma-controller@01c02000";
		tcon0 = "/soc/lcd-controller@1c0c000";
		tcon0_in = "/soc/lcd-controller@1c0c000/ports/port@0";
		tcon0_in_mixer0 = "/soc/lcd-controller@1c0c000/ports/port@0/endpoint@0";
		tcon0_in_mixer1 = "/soc/lcd-controller@1c0c000/ports/port@0/endpoint@1";
		tcon0_out = "/soc/lcd-controller@1c0c000/ports/port@1";
		tcon0_out_hdmi = "/soc/lcd-controller@1c0c000/ports/port@1/endpoint@1";
		tcon1 = "/soc/lcd-controller@1c0d000";
		tcon1_in = "/soc/lcd-controller@1c0d000/ports/port@0";
		tcon1_in_mixer0 = "/soc/lcd-controller@1c0d000/ports/port@0/endpoint@0";
		tcon1_in_mixer1 = "/soc/lcd-controller@1c0d000/ports/port@0/endpoint@1";
		tcon1_out = "/soc/lcd-controller@1c0d000/ports/port@1";
		mmc0 = "/soc/mmc@01c0f000";
		mmc1 = "/soc/mmc@01c10000";
		mmc2 = "/soc/mmc@01c11000";
		usb_otg = "/soc/usb@01c19000";
		usbphy = "/soc/phy@01c19400";
		ehci0 = "/soc/usb@01c1a000";
		ohci0 = "/soc/usb@01c1a400";
		ehci1 = "/soc/usb@01c1b000";
		ohci1 = "/soc/usb@01c1b400";
		ehci2 = "/soc/usb@01c1c000";
		ohci2 = "/soc/usb@01c1c400";
		ehci3 = "/soc/usb@01c1d000";
		ohci3 = "/soc/usb@01c1d400";
		ccu = "/soc/clock@01c20000";
		pio = "/soc/pinctrl@01c20800";
		emac_rgmii_pins = "/soc/pinctrl@01c20800/emac0";
		i2c0_pins = "/soc/pinctrl@01c20800/i2c0";
		i2c1_pins = "/soc/pinctrl@01c20800/i2c1";
		i2c2_pins = "/soc/pinctrl@01c20800/i2c2";
		i2s0_pins = "/soc/pinctrl@01c20800/i2s0";
		i2s1_pins = "/soc/pinctrl@01c20800/i2s1";
		mmc0_pins_a = "/soc/pinctrl@01c20800/mmc0@0";
		mmc0_cd_pin = "/soc/pinctrl@01c20800/mmc0_cd_pin@0";
		mmc1_pins_a = "/soc/pinctrl@01c20800/mmc1@0";
		mmc2_8bit_pins = "/soc/pinctrl@01c20800/mmc2_8bit";
		spdif_tx_pins_a = "/soc/pinctrl@01c20800/spdif@0";
		spi0_pins = "/soc/pinctrl@01c20800/spi0";
		spi1_pins = "/soc/pinctrl@01c20800/spi1";
		uart0_pins_a = "/soc/pinctrl@01c20800/uart0@0";
		uart1_pins = "/soc/pinctrl@01c20800/uart1";
		uart1_rts_cts_pins = "/soc/pinctrl@01c20800/uart1_rts_cts";
		uart2_pins = "/soc/pinctrl@01c20800/uart2";
		uart3_pins = "/soc/pinctrl@01c20800/uart3";
		uart3_rts_cts_pins = "/soc/pinctrl@01c20800/uart3_rts_cts";
		leds_npi = "/soc/pinctrl@01c20800/led_pins@0";
		emac = "/soc/ethernet@1c30000";
		mdio = "/soc/ethernet@1c30000/mdio";
		internal_mdio = "/soc/ethernet@1c30000/mdio-mux/mdio@1";
		int_mii_phy = "/soc/ethernet@1c30000/mdio-mux/mdio@1/ethernet-phy@1";
		external_mdio = "/soc/ethernet@1c30000/mdio-mux/mdio@2";
		spi0 = "/soc/spi@01c68000";
		spi1 = "/soc/spi@01c69000";
		wdt0 = "/soc/watchdog@01c20ca0";
		spdif = "/soc/spdif@01c21000";
		pwm = "/soc/pwm@01c21400";
		i2s0 = "/soc/i2s@01c22000";
		i2s1 = "/soc/i2s@01c22400";
		i2s2 = "/soc/i2s@1c22800";
		codec = "/soc/codec@01c22c00";
		uart0 = "/soc/serial@01c28000";
		uart1 = "/soc/serial@01c28400";
		uart2 = "/soc/serial@01c28800";
		uart3 = "/soc/serial@01c28c00";
		i2c0 = "/soc/i2c@01c2ac00";
		i2c1 = "/soc/i2c@01c2b000";
		i2c2 = "/soc/i2c@01c2b400";
		gic = "/soc/interrupt-controller@01c81000";
		rtc = "/soc/rtc@01f00000";
		r_ccu = "/soc/clock@1f01400";
		codec_analog = "/soc/codec-analog@01f015c0";
		ir = "/soc/ir@01f02000";
		r_i2c = "/soc/i2c@01f02400";
		r_pio = "/soc/pinctrl@01f02c00";
		ir_pins_a = "/soc/pinctrl@01f02c00/ir@0";
		r_i2c_pins = "/soc/pinctrl@01f02c00/r-i2c";
		leds_r_npi = "/soc/pinctrl@01f02c00/led_pins@0";
		sw_r_npi = "/soc/pinctrl@01f02c00/key_pins@0";
		ths = "/soc/thermal-sensor@1c25000";
		mali = "/soc/gpu@1c40000";
		cpu_opp_table = "/opp_table";
		cpu0 = "/cpus/cpu@0";
		cpu_warm = "/thermal-zones/cpu-thermal/trips/cpu_warm";
		cpu_hot_pre = "/thermal-zones/cpu-thermal/trips/cpu_hot_pre";
		cpu_hot = "/thermal-zones/cpu-thermal/trips/cpu_hot";
		cpu_very_hot_pre = "/thermal-zones/cpu-thermal/trips/cpu_very_hot_pre";
		cpu_very_hot = "/thermal-zones/cpu-thermal/trips/cpu_very_hot";
		cpu_crit = "/thermal-zones/cpu-thermal/trips/cpu_crit";
		cma = "/reserved-memory/linux,cma";
		reg_cpu_fallback = "/reg_cpu_fallback";
		reg_ahci_5v = "/ahci-5v";
		reg_usb0_vbus = "/usb0-vbus";
		reg_usb1_vbus = "/usb1-vbus";
		reg_usb2_vbus = "/usb2-vbus";
		reg_vcc3v0 = "/vcc3v0";
		reg_vcc3v3 = "/vcc3v3";
		reg_vcc5v0 = "/vcc5v0";
	};
};
